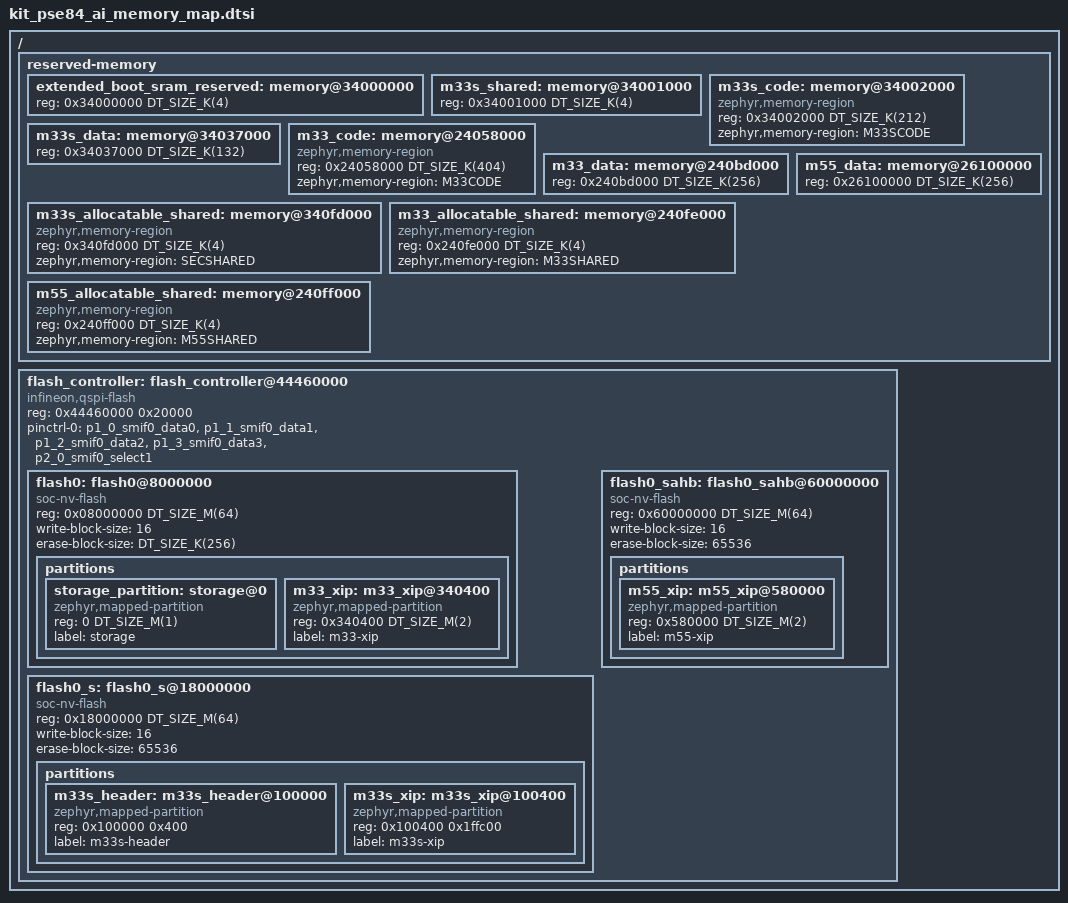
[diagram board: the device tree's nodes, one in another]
/*
 * SPDX-FileCopyrightText: Copyright (c) 2026 Infineon Technologies AG,
 * SPDX-FileCopyrightText: or an affiliate of Infineon Technologies AG. All rights reserved.
 *
 * SPDX-License-Identifier: Apache-2.0
 */

/ {
	/* Default SRAM(1MB) assignment
	 * - Lowest 4kb reserved for the Extended boot
	 * - 4kb shared between CM33 secure project and secure enclave
	 * - 212 kB allocated to CM33 Secure code
	 * - 132 kB allocated to CM33 Secure data
	 * - 404 kB allocated to CM33 Non-Secure code
	 * - 256 kB allocated to the CM33 Non-Secure data
	 * - 4 kB allocated to shared memory for each core (cm33_s, cm33 and cm55)
	 */
	reserved-memory {
		ranges;
		#address-cells = <1>;
		#size-cells = <1>;

		extended_boot_sram_reserved: memory@34000000 {
			reg = <0x34000000 DT_SIZE_K(4)>;
		};

		m33s_shared: memory@34001000 {
			reg = <0x34001000 DT_SIZE_K(4)>;
		};

		m33s_code: memory@34002000 {
			compatible = "zephyr,memory-region", "mmio-sram";
			reg = <0x34002000 DT_SIZE_K(212)>;
			zephyr,memory-region = "M33SCODE";
		};

		m33s_data: memory@34037000 {
			reg = <0x34037000 DT_SIZE_K(132)>;
		};

		m33_code: memory@24058000 {
			compatible = "zephyr,memory-region", "mmio-sram";
			reg = <0x24058000 DT_SIZE_K(404)>;
			zephyr,memory-region = "M33CODE";
		};

		m33_data: memory@240bd000 {
			reg = <0x240bd000 DT_SIZE_K(256)>;
		};

		m33s_allocatable_shared: memory@340fd000 {
			compatible = "zephyr,memory-region", "mmio-sram";
			reg = <0x340fd000 DT_SIZE_K(4)>;
			zephyr,memory-region = "SECSHARED";
		};

		m33_allocatable_shared: memory@240fe000 {
			compatible = "zephyr,memory-region", "mmio-sram";
			reg = <0x240fe000 DT_SIZE_K(4)>;
			zephyr,memory-region = "M33SHARED";
		};

		m55_allocatable_shared: memory@240ff000 {
			compatible = "zephyr,memory-region", "mmio-sram";
			reg = <0x240ff000 DT_SIZE_K(4)>;
			zephyr,memory-region = "M55SHARED";
		};

		m55_data: memory@26100000 {
			reg = <0x26100000 DT_SIZE_K(256)>;
		};
	};

	/* Default Flash memory(64MB) assignment
	 * - Lowest 1MB reserved for Storage
	 * - 2MB for each of the cores(cm33_s, cm33 and cm55)
	 */
	flash_controller: flash_controller@44460000 {
		compatible = "infineon,qspi-flash";
		reg = <0x44460000 0x20000>;
		ranges;
		#address-cells = <1>;
		#size-cells = <1>;

		pinctrl-0 = <&p1_0_smif0_data0 &p1_1_smif0_data1
			     &p1_2_smif0_data2 &p1_3_smif0_data3
			     &p2_0_smif0_select1>;
		pinctrl-names = "default";

		/* CBUS non-secure view of external flash.
		 * Used as zephyr,flash for NS builds.
		 * The base address is 0x08000000.
		 */
		flash0: flash0@8000000 {
			compatible = "soc-nv-flash", "infineon,s25hs512t";
			reg = <0x08000000 DT_SIZE_M(64)>;
			ranges = <0x0 0x08000000 DT_SIZE_M(64)>;
			#address-cells = <1>;
			#size-cells = <1>;
			write-block-size = <16>;
			erase-block-size = <DT_SIZE_K(256)>;

			partitions {
				ranges;
				#address-cells = <1>;
				#size-cells = <1>;

				storage_partition: storage@0 {
					compatible = "zephyr,mapped-partition";
					reg = <0 DT_SIZE_M(1)>;
					label = "storage";
				};

				m33_xip: m33_xip@340400 {
					compatible = "zephyr,mapped-partition";
					reg = <0x340400 DT_SIZE_M(2)>;
					label = "m33-xip";
				};
			};
		};

		/* CBUS secure view of the same external flash.
		 * Used as zephyr,flash for S builds.
		 * The base address is 0x18000000.
		 * This is the same physical device as flash0, accessed
		 * through the secure CBUS alias for instruction-cached
		 * execution in secure mode.
		 */
		flash0_s: flash0_s@18000000 {
			compatible = "soc-nv-flash";
			reg = <0x18000000 DT_SIZE_M(64)>;
			ranges = <0x0 0x18000000 DT_SIZE_M(64)>;
			#address-cells = <1>;
			#size-cells = <1>;
			write-block-size = <16>;
			erase-block-size = <65536>;

			partitions {
				ranges;
				#address-cells = <1>;
				#size-cells = <1>;

				m33s_header: m33s_header@100000 {
					compatible = "zephyr,mapped-partition";
					reg = <0x100000 0x400>;
					label = "m33s-header";
				};

				m33s_xip: m33s_xip@100400 {
					compatible = "zephyr,mapped-partition";
					reg = <0x100400 0x1ffc00>;
					label = "m33s-xip";
				};
			};
		};

		/* SAHB view of the same external flash.
		 * Used as zephyr,flash for CM55 builds.
		 * The base address is 0x70000000.
		 * This is the same physical device as flash0, accessed
		 * through the SAHB alias as cm55 does not have
		 * instruction-cached execution for external flash.
		 */
		flash0_sahb: flash0_sahb@60000000 {
			compatible = "soc-nv-flash";
			reg = <0x60000000 DT_SIZE_M(64)>;
			ranges = <0x0 0x60000000 DT_SIZE_M(64)>;
			#address-cells = <1>;
			#size-cells = <1>;
			write-block-size = <16>;
			erase-block-size = <65536>;

			partitions {
				ranges;
				#address-cells = <1>;
				#size-cells = <1>;

				m55_xip: m55_xip@580000 {
					compatible = "zephyr,mapped-partition";
					reg = <0x580000 DT_SIZE_M(2)>;
					label = "m55-xip";
				};
			};
		};
	};
};
